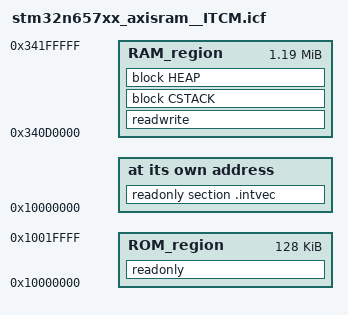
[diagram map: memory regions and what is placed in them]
/*###ICF### Section handled by ICF editor, don't touch! ****/
/*-Editor annotation file-*/
/* IcfEditorFile="$TOOLKIT_DIR$\config\ide\IcfEditor\cortex_v1_0.xml" */
/*-Specials-*/
define symbol __ICFEDIT_intvec_start__ = 0x10000000;
/*-Memory Regions-*/
define symbol __ICFEDIT_region_ROM_start__ = 0x10000000;         /* ITCM with retention (128kB) */
define symbol __ICFEDIT_region_ROM_end__   = 0x1001FFFF;
define symbol __ICFEDIT_region_RAM_start__ = 0x340D0000;
define symbol __ICFEDIT_region_RAM_end__   = 0x341FFFFF;       /* AXISRAM2 end */

/*-Sizes-*/
define symbol __ICFEDIT_size_cstack__ = 0x4000;    // 28 KB
define symbol __ICFEDIT_size_heap__   = 0x2000;    // 28 KB
/**** End of ICF editor section. ###ICF###*/

define symbol region_ITCM_start = 0x10000000;
define symbol region_ITCM_end   = 0x1001FFFF; // ITCM base line
define symbol region_DTCM_start = 0x30000000;
define symbol region_DTCM_end   = 0x3001FFFF; // DTCM base line

define memory mem with size = 4G;
define region ROM_region      = mem:[from __ICFEDIT_region_ROM_start__ to __ICFEDIT_region_ROM_end__]; /* 1024 KB */
define region RAM_region      = mem:[from __ICFEDIT_region_RAM_start__ to __ICFEDIT_region_RAM_end__]; /* 1024 KB */

define block CSTACK    with alignment = 8, size = __ICFEDIT_size_cstack__   { };
define block HEAP      with alignment = 8, size = __ICFEDIT_size_heap__     { };

initialize by copy { readwrite };
do not initialize  { section .noinit };

place at address mem:__ICFEDIT_intvec_start__ { readonly section .intvec };

place in ROM_region   { readonly };
place in RAM_region   { readwrite, block CSTACK, block HEAP };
